# GD32W515 register map
File version: 1.0
CPU: CM33 r0p4, little endian, MPU, FPU, 4 interrupt priority bits
Registers are 32-bit, read-write, reset 0x0 unless marked. A register's access mark holds for its fields unless they carry their own. Offsets are from the block's base; [hi:lo] are bit positions; {n}, {i} and the like mark numbered series.

## FMC — Flash memory controller
Base 0x40022000
Same registers: SEC_FMC 0x50022000
0x04 KEY wo — Unlock key register
  [31:0] KEY — FMC_CTL unlock register
0x08 OBKEY wo — Option byte unlock key register
  [31:0] OBKEY — These bits are only be written by software.
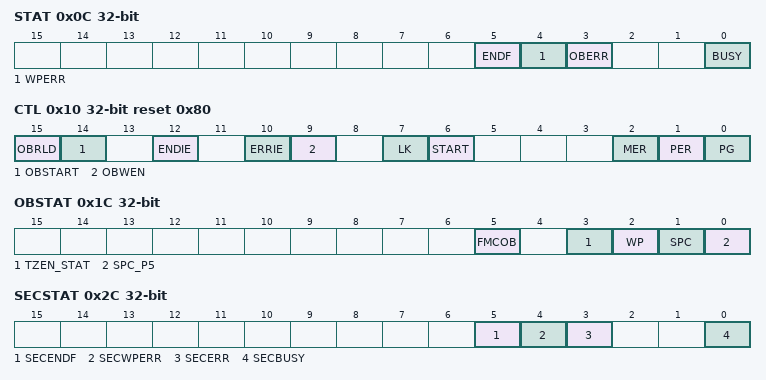
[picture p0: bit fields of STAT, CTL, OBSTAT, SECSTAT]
0x0C STAT access per field — Status register
  [5] ENDF rw — End of operation flag bit
  [4] WPERR rw — Erase/Program protection error flag bit
  [3] OBERR rw — Option bytes error flag bit (If there are option bytes)
  [0] BUSY ro — The Flash is busy bit
0x10 CTL reset 0x80 — Control register
  [15] OBRLD — Option byte reload bit
  [14] OBSTART — Option bytes modification start bit
  [12] ENDIE — End of operation interrupt enable bit
  [10] ERRIE — Error interrupt enable bit
  [9] OBWEN — FMC_OBR / FMC_OBUSER / FMC_SECMx (x=0,1,2,3) / FMC_NODECx (x=0,1,2,3) / FMC_OFRG / FMC_OFVR / FMC_OBWRPx (x=0,1) write enable bit
  [7] LK — FMC_CTL lock bit
  [6] START — Send erase command to FMC
  [2] MER — Main Flash mass erase command bit
  [1] PER — Main Flash page erase command bit
  [0] PG — Main Flash program command bit
0x14 ADDR wo — Address register
  [31:0] ADDR — Flash erase/program command address bits
0x1C OBSTAT ro — Option byte status register
  [5] FMCOB — Whether the option byte exist or not.
  [3] TZEN_STAT — Trust zone state
  [2] WP — Write/erase protection state
  [1] SPC — Security protection level 1 state
  [0] SPC_P5 — Security protection level 0.5 state
0x24 SECKEY wo — Secure Unlock key register
  [31:0] SECKEY — FMC_SECCTL unlock register
0x2C SECSTAT access per field — Secure status register
  [5] SECENDF rw — End of operation flag
  [4] SECWPERR rw — Erase/Program protection error flag
  [3] SECERR rw — Secure error flag (If there are no option bytes)
  [0] SECBUSY ro — The Flash is busy
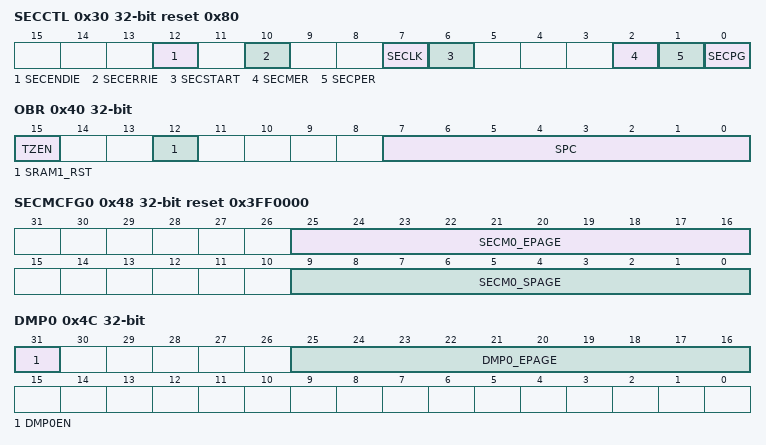
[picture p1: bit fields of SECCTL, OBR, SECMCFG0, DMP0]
0x30 SECCTL reset 0x80 — Secure Control register
  [12] SECENDIE — End of operation interrupt enable bit
  [10] SECERRIE — Error interrupt enable bit
  [7] SECLK — FMC_SECCTL lock bit
  [6] SECSTART — Send erase command to FMC bit
  [2] SECMER — Main Flash mass erase command bit
  [1] SECPER — Main Flash page erase command bit
  [0] SECPG — Main Flash program command bit
0x34 SECADDR wo — Secure Address register
  [31:0] SECADDR — Flash erase/program command address bits
0x40 OBR — Option byte register
  [15] TZEN — Trust zone enable bit
  [12] SRAM1_RST — SRAM1 reset enable bit
  [7:0] SPC — Flash security protection value. Effective after system reset.
0x44 OBUSER — Option byte user register
  [15:0] USER — Option byte USER value.
0x48 SECMCFG0 reset 0x3FF0000 — Secure mark configuration register 0
  [25:16] SECM0_EPAGE — End page of secure mark area 0.
  [9:0] SECM0_SPAGE — Start page of secure mark area 0.
0x4C DMP0 — Secure dedicated mark protection register 0
  [31] DMP0EN — DMP area 0 enable
  [25:16] DMP0_EPAGE — End page of DMP area 0.
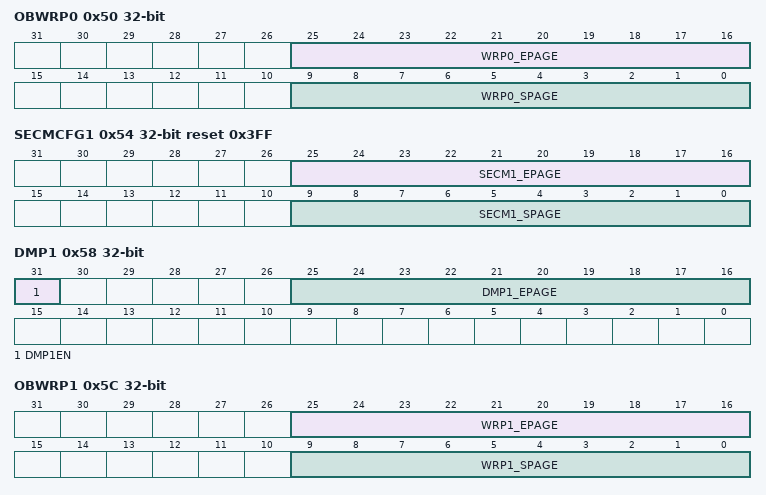
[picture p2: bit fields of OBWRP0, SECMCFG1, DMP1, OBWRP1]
0x50 OBWRP0 — Option byte write protection area register 0
  [25:16] WRP0_EPAGE — End page of write protection area 0
  [9:0] WRP0_SPAGE — Start page of write protection area 0
0x54 SECMCFG1 reset 0x3FF — Secure mark configuration register 1
  [25:16] SECM1_EPAGE — End page of secure mark area 1.
  [9:0] SECM1_SPAGE — Start page of secure mark area 1.
0x58 DMP1 — Secure dedicated mark protection register 1
  [31] DMP1EN — DMP area 1 enable
  [25:16] DMP1_EPAGE — End page of DMP area 1.
0x5C OBWRP1 — Option byte write protection area register 1
  [25:16] WRP1_EPAGE — End page of write protection area 1
  [9:0] WRP1_SPAGE — Start page of write protection area 1
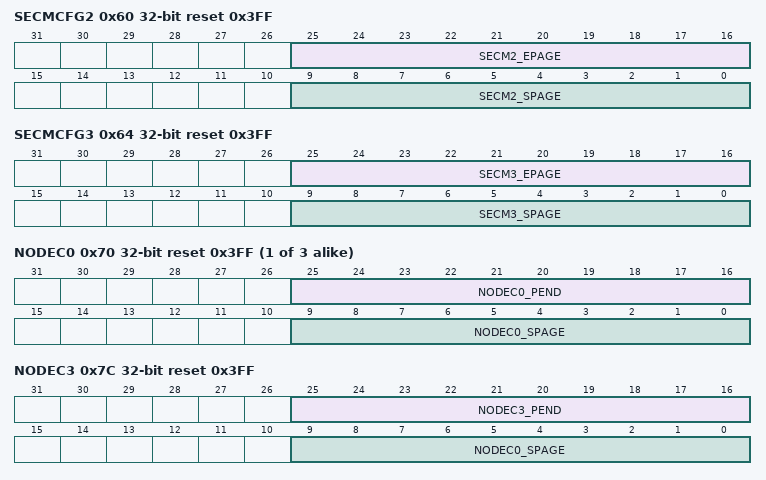
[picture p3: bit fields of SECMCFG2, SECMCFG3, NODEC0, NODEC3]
0x60 SECMCFG2 reset 0x3FF — Secure mark configuration register
  [25:16] SECM2_EPAGE — End page of secure mark area 2.
  [9:0] SECM2_SPAGE — Start page of secure mark area 2.
0x64 SECMCFG3 reset 0x3FF — Secure mark configuration register 3
  [25:16] SECM3_EPAGE — End page of secure mark area 3.
  [9:0] SECM3_SPAGE — Start page of secure mark area 3.
{0x70+4i} NODEC{i} reset 0x3FF (i=0..2) — NO OTFDEC region{i} register
  [25:16] NODEC{i}_PEND — End page of NODEC region {i}
  [9:0] NODEC{i}_SPAGE — Start page of NODEC region {i}
0x7C NODEC3 reset 0x3FF — NO OTFDEC region3 register
  [25:16] NODEC3_PEND — End page of NODEC region 3
  [9:0] NODEC0_SPAGE — Start page of NODEC region 3
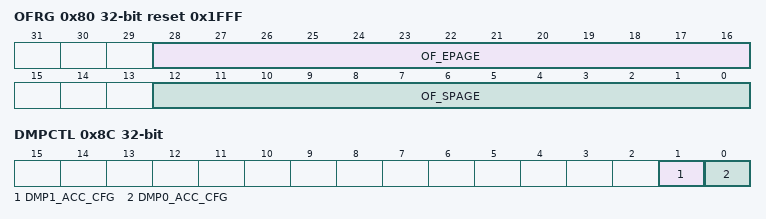
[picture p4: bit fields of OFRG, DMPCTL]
0x80 OFRG reset 0x1FFF — Offset region register
  [28:16] OF_EPAGE — End page of offset region
  [12:0] OF_SPAGE — Start page of offset region
0x84 OFVR — Offset value register
  [12:0] OF_VALUE — Offset value
0x8C DMPCTL — DMP control register
  [1] DMP1_ACC_CFG — DMP area 1 access configuration bit
  [0] DMP0_ACC_CFG — DMP area 0 access configuration bit
0x90 PRIVCFG — Privilege configuration register
  [0] FMC_PRIV — FMC privilege configuration
0x100 PID ro — Product ID register
  [31:0] PID — Product reserved ID code register
